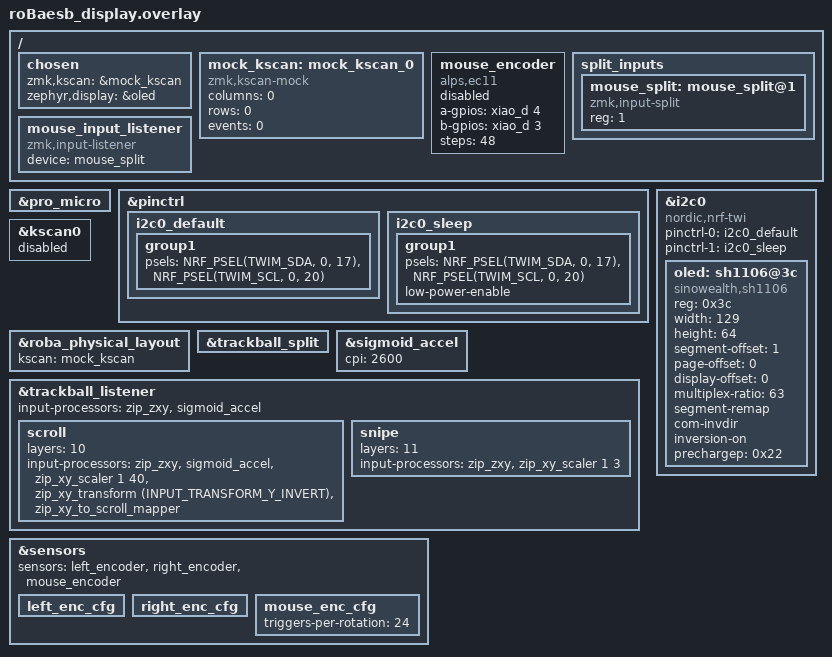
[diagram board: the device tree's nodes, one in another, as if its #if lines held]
xiao_d: &pro_micro {};

#include "../roBa/roBa.dtsi"
#ifdef ZMK_ESB_ADDR_B
#include "roBaesb_addr_b.dtsi"
#else
#include "roBaesb_addr.dtsi"
#endif
#include <input/processors/xyz.dtsi>
#include <behaviors/input_processor_sigmoid_accel.dtsi>

#ifdef ZMK_ESB_MOUSE
/* Extend the transform + physical layout to include 5 lariska button positions */
#include "roBaesb_lariska_transform.dtsi"
#endif

/ {
    chosen {
        zmk,kscan = &mock_kscan;
        zephyr,display = &oled;
    };

    mock_kscan: mock_kscan_0 {
        compatible = "zmk,kscan-mock";
        columns = <0>;
        rows = <0>;
        events = <0>;
    };

#ifdef ZMK_ESB_MOUSE
    /* Disabled placeholder for the lariska encoder at sensor slot 2.
     * The QDEC on peripheral 2 sends sensor-index 2 → this slot → keymap
     * sensor-bindings[2]. GPIO refs are dummy (node is disabled). */
    mouse_encoder: mouse_encoder {
        compatible = "alps,ec11";
        a-gpios = <&xiao_d 4 (GPIO_ACTIVE_HIGH | GPIO_PULL_UP)>;
        b-gpios = <&xiao_d 3 (GPIO_ACTIVE_HIGH | GPIO_PULL_UP)>;
        steps = <48>;
        status = "disabled";
    };

    /* Add mouse_split@1 alongside trackball_split@0 (from roBa.dtsi).
     * Receives PAW3395 input events forwarded by the lariska peripheral. */
    split_inputs {
        mouse_split: mouse_split@1 {
            compatible = "zmk,input-split";
            reg = <1>;
            status = "okay";
        };
    };

    /* Mouse input listener — NO sigmoid_accel so the mouse movement stays
     * linear. Sigmoid accel is applied only to the roBa trackball below. */
    mouse_input_listener: mouse_input_listener {
        compatible = "zmk,input-listener";
        status = "okay";
        device = <&mouse_split>;
    };
#endif
};

&pinctrl {
    i2c0_default: i2c0_default {
        group1 {
            psels = <NRF_PSEL(TWIM_SDA, 0, 17)>,
                <NRF_PSEL(TWIM_SCL, 0, 20)>;
        };
    };

    i2c0_sleep: i2c0_sleep {
        group1 {
            psels = <NRF_PSEL(TWIM_SDA, 0, 17)>,
                <NRF_PSEL(TWIM_SCL, 0, 20)>;
            low-power-enable;
        };
    };
};

&i2c0 {
    status = "okay";
    compatible = "nordic,nrf-twi";
    pinctrl-0 = <&i2c0_default>;
    pinctrl-1 = <&i2c0_sleep>;

    oled: sh1106@3c {
        compatible = "sinowealth,sh1106";
        reg = <0x3c>;
        width = <129>;
        height = <64>;
        segment-offset = <1>;
        page-offset = <0>;
        display-offset = <0>;
        multiplex-ratio = <63>;
        segment-remap;
        com-invdir;
        inversion-on;
        prechargep = <0x22>;
    };
};

&kscan0 {
    status = "disabled";
};

&roba_physical_layout {
    kscan = <&mock_kscan>;
};

&trackball_split {
    status = "okay";
};

&sigmoid_accel {
    cpi = <2600>;
};

/* sigmoid_accel applied ONLY to the roBa right-side trackball listener.
 * The lariska mouse (mouse_input_listener above) has no sigmoid_accel. */
&trackball_listener {
    status = "okay";
    input-processors = <&zip_zxy>, <&sigmoid_accel>;

    scroll {
        layers = <10>;
        input-processors = <&zip_zxy>, <&sigmoid_accel>, <&zip_xy_scaler 1 40>, <&zip_xy_transform (INPUT_TRANSFORM_Y_INVERT)>, <&zip_xy_to_scroll_mapper>;
    };

    snipe {
        layers = <11>;
        input-processors = <&zip_zxy>, <&zip_xy_scaler 1 3>;
    };
};

#ifdef ZMK_ESB_MOUSE
/* Add the lariska encoder at sensor slot 2 (after left and right encoders).
 * Child-binding (one node per sensor in order) sets per-sensor triggers-per-rotation. */
&sensors {
    sensors = <&left_encoder &right_encoder &mouse_encoder>;
    left_enc_cfg: left_enc_cfg {};
    right_enc_cfg: right_enc_cfg {};
    mouse_enc_cfg: mouse_enc_cfg {
        triggers-per-rotation = <24>;
    };
};
#endif
